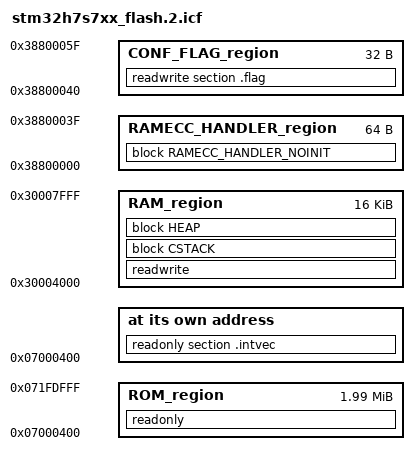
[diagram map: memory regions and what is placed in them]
/*###ICF### Section handled by ICF editor, don't touch! ****/
/*-Editor annotation file-*/
/* IcfEditorFile="$TOOLKIT_DIR$\config\ide\IcfEditor\cortex_v1_0.xml" */
/*-Specials-*/
define exported symbol CODE_OFFSET = 0x0; /* This define is updated automatically from OEMiROT_BOOT project */
define exported symbol CODE_SIZE = 0x200000; /* This define is updated automatically from OEMiROT_BOOT project */
define exported symbol PARTITION_START = 0x7000000; /* This define is updated automatically from OEMiROT_BOOT project */
define exported symbol IMAGE_HEADER_SIZE = 0x400; /* mcuboot header size */
define symbol TRAILER_MAX_SIZE = 0x2000; /* Trailer max size */
define exported symbol __ICFEDIT_intvec_start__ = PARTITION_START + CODE_OFFSET + IMAGE_HEADER_SIZE;
/*-Memory Regions-*/
define symbol __ICFEDIT_region_ROM_start__ = PARTITION_START + CODE_OFFSET + IMAGE_HEADER_SIZE;
define symbol __ICFEDIT_region_ROM_end__   = PARTITION_START + CODE_OFFSET + CODE_SIZE - TRAILER_MAX_SIZE - 1;
define symbol __ICFEDIT_region_RAM_start__ = 0x30004000;
define symbol __ICFEDIT_region_RAM_end__   = 0x30007FFF;

define symbol __ICFEDIT_region_RAMECC_HANDLER_start__ = 0x38800000;
define symbol __ICFEDIT_region_RAMECC_HANDLER_end__   = 0x3880003F;

define exported symbol __ICFEDIT_region_CONF_FLAG_start__ = __ICFEDIT_region_RAMECC_HANDLER_end__ + 1;
define exported symbol __ICFEDIT_region_CONF_FLAG_end__   = 0x3880005F;

/*-Sizes-*/
define symbol __ICFEDIT_size_cstack__ = 0x400;
define symbol __ICFEDIT_size_heap__   = 0x200;
/**** End of ICF editor section. ###ICF###*/


define memory mem with size = 4G;
define region ROM_region            = mem:[from __ICFEDIT_region_ROM_start__            to __ICFEDIT_region_ROM_end__];
define region RAM_region            = mem:[from __ICFEDIT_region_RAM_start__            to __ICFEDIT_region_RAM_end__];
define region RAMECC_HANDLER_region = mem:[from __ICFEDIT_region_RAMECC_HANDLER_start__ to __ICFEDIT_region_RAMECC_HANDLER_end__];
define region CONF_FLAG_region      = mem:[from __ICFEDIT_region_CONF_FLAG_start__      to __ICFEDIT_region_CONF_FLAG_end__];

define block CSTACK    with alignment = 8, size = __ICFEDIT_size_cstack__   { };
define block HEAP      with alignment = 8, size = __ICFEDIT_size_heap__     { };

initialize by copy { readwrite };
do not initialize  { section .noinit };
do not initialize  { section .ramecchandlernoinit };

define block RAMECC_HANDLER_NOINIT { section .ramecchandlernoinit};

place at address mem:__ICFEDIT_intvec_start__ { readonly section .intvec };

place in ROM_region            { readonly };
place in RAM_region            { readwrite,
                                  block CSTACK, block HEAP };
place in RAMECC_HANDLER_region { block RAMECC_HANDLER_NOINIT };
place in CONF_FLAG_region      { readwrite section .flag };
keep { section .flag };
